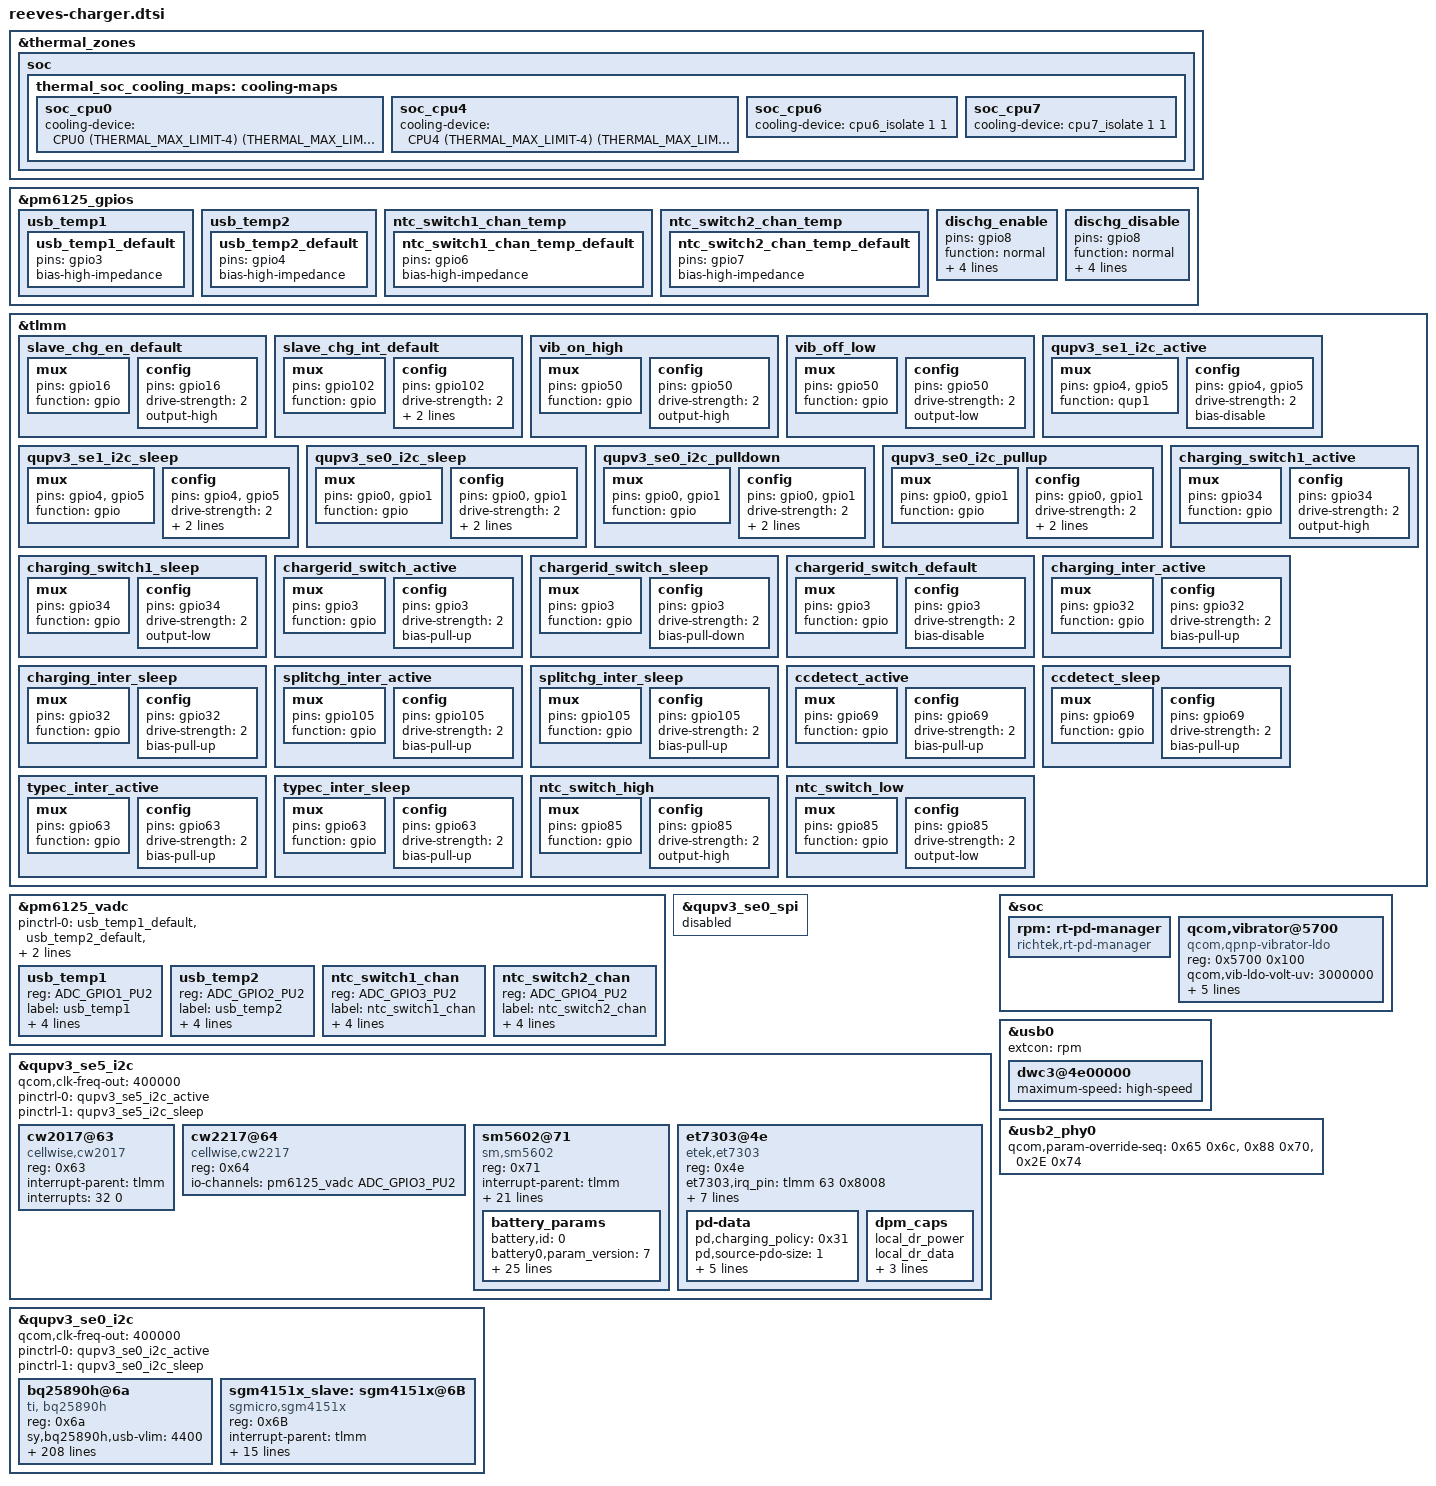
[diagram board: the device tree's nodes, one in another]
/*
&smb1355 {
	/delete-property/ pinctrl-names;
	/delete-property/ pinctrl-0;
	/delete-property/ interrupt-parent;
	/delete-property/ interrupts;
	/delete-property/ status;

	status = "disabled";
};

&smb1355_charger {
	/delete-property/ pinctrl-names;
	/delete-property/ pinctrl-0;
	/delete-property/ qcom,parallel-mode;
	/delete-property/ qcom,disable-ctm;
	/delete-property/ qcom,hw-die-temp-mitigation;
	/delete-property/ status;

	status = "disabled";
};


&dsi_td4330_truly_v2_video {
	/delete-property/ qcom,platform-bklight-en-gpio;
};

&dsi_td4330_truly_v2_cmd {
	/delete-property/ qcom,platform-bklight-en-gpio;
};

&sde_dsi {
	/delete-property/ lab-supply;
	/delete-property/ ibb-supply;
};
*/
&thermal_zones {
	soc {
		thermal_soc_cooling_maps: cooling-maps {
			soc_cpu0 {
				//trip = <&pmi632_low_soc>;
				cooling-device =
					<&CPU0 (THERMAL_MAX_LIMIT-4)
						(THERMAL_MAX_LIMIT-4)>;
			};

			soc_cpu4 {
				//trip = <&pmi632_low_soc>;
				cooling-device =
					<&CPU4 (THERMAL_MAX_LIMIT-4)
						(THERMAL_MAX_LIMIT-4)>;
			};

			soc_cpu6 {
				//trip = <&pmi632_low_soc>;
				cooling-device = <&cpu6_isolate 1 1>;
			};

			soc_cpu7 {
				//trip = <&pmi632_low_soc>;
				cooling-device = <&cpu7_isolate 1 1>;
			};
		};
	};
};

/*split charger dts config*/
&pm6125_gpios {
	usb_temp1 {
		usb_temp1_default: usb_temp1_default {
			pins = "gpio3";
			bias-high-impedance;
		};
	};

	usb_temp2 {
		usb_temp2_default: usb_temp2_default {
			pins = "gpio4";
			bias-high-impedance;
		};
	};

	ntc_switch1_chan_temp {
		ntc_switch1_chan_temp_default: ntc_switch1_chan_temp_default {
			pins = "gpio6";
			bias-high-impedance;
		};
	};

	ntc_switch2_chan_temp {
		ntc_switch2_chan_temp_default: ntc_switch2_chan_temp_default {
			pins = "gpio7";
			bias-high-impedance;
		};
	};

	dischg_enable: dischg_enable {
		pins = "gpio8";
		function = "normal";
		power-source = <0>;
		output-high;
		input-disable;
		qcom,drive-strength = <2>;
	};

	dischg_disable: dischg_disable {
		pins = "gpio8";
		function = "normal";
		power-source = <0>;
		output-low;
		input-disable;
		qcom,drive-strength = <2>;
	};
};

&tlmm {
			slave_chg_en_default: slave_chg_en_default {
				mux {
					pins = "gpio16";
					function = "gpio";
				};

				config {
					pins = "gpio16";
					drive-strength = <2>;
					output-high;
				};
			};

			slave_chg_int_default: slave_chg_int_default {
				mux {
					pins = "gpio102";
					function = "gpio";
				};

				config {
					pins = "gpio102";
					drive-strength = <2>;
					input-enable;
					bias-pull-up;
				};
			};


			vib_on_high: vib_on_high {
				mux {
					pins = "gpio50";
					function = "gpio";
				};

				config {
					pins = "gpio50";
					drive-strength = <2>;
					output-high;
				};
			};
			vib_off_low: vib_off_low {
				mux {
					pins = "gpio50";
					function = "gpio";
				};

				config {
					pins = "gpio50";
					drive-strength = <2>;
					output-low;
				};
			};
			qupv3_se1_i2c_active: qupv3_se1_i2c_active {
				mux {
					pins = "gpio4", "gpio5";
					function = "qup1";
				};

				config {
					pins = "gpio4", "gpio5";
					drive-strength = <2>;
					bias-disable;
				};
			};
			qupv3_se1_i2c_sleep: qupv3_se1_i2c_sleep {
				mux {
					pins = "gpio4", "gpio5";
					function = "gpio";
				};

				config {
					pins = "gpio4", "gpio5";
					drive-strength = <2>;
					bias-no-pull;
					output-high;
				};
			};
			qupv3_se0_i2c_sleep: qupv3_se0_i2c_sleep {
				mux {
					pins = "gpio0", "gpio1";
					function = "gpio";
				};

				config {
					pins = "gpio0", "gpio1";
					drive-strength = <2>;
					bias-no-pull;
					output-high;
				};
			};

			qupv3_se0_i2c_pulldown: qupv3_se0_i2c_pulldown {
				mux {
					pins = "gpio0", "gpio1";
					function = "gpio";
				};

				config {
					pins = "gpio0", "gpio1";
					drive-strength = <2>;
					bias-pull-down;
					output-low;
				};
			};

			qupv3_se0_i2c_pullup: qupv3_se0_i2c_pullup {
				mux {
					pins = "gpio0", "gpio1";
					function = "gpio";
				};

				config {
					pins = "gpio0", "gpio1";
					drive-strength = <2>;
					bias-pull-up;
					input-enable;
				};
			};

			charging_switch1_active: charging_switch1_active {
				mux {
					pins = "gpio34";
					function = "gpio";
				};

				config {
					pins = "gpio34";
					drive-strength = <2>;
					output-high;
				};
			};

			charging_switch1_sleep: charging_switch1_sleep {
				mux {
					pins = "gpio34";
					function = "gpio";
				};

				config {
					pins = "gpio34";
					drive-strength = <2>;
					output-low;
				};
			};

			chargerid_switch_active: chargerid_switch_active {
				mux {
					pins = "gpio3";
					function = "gpio";
				};

				config {
					pins = "gpio3";
					drive-strength = <2>;
					bias-pull-up;
				};
			};

			chargerid_switch_sleep: chargerid_switch_sleep {
				mux {
					pins = "gpio3";
					function = "gpio";
				};

				config {
					pins = "gpio3";
					drive-strength = <2>;
					bias-pull-down;
				};
			};

			chargerid_switch_default: chargerid_switch_default {
				mux {
					pins = "gpio3";
					function = "gpio";
				};

				config {
					pins = "gpio3";
					drive-strength = <2>;
					bias-disable; /* NO PULL */
				};
			};

             charging_inter_active: charging_inter_active {
                     mux {
                             pins = "gpio32";
                             function = "gpio";
                     };

                     config {
                             pins = "gpio32";
                             drive-strength = <2>;
                             bias-pull-up;
                     };
             };

             charging_inter_sleep: charging_inter_sleep {
                     mux {
                             pins = "gpio32";
                             function = "gpio";
                     };

                     config {
                             pins = "gpio32";
                             drive-strength = <2>;
                             bias-pull-up;
                     };
            };

             /*split_chg*/
             splitchg_inter_active: splitchg_inter_active {
                     mux {
                             pins = "gpio105";
                             function = "gpio";
                     };

                     config {
                             pins = "gpio105";
                             drive-strength = <2>;
                             bias-pull-up;
                     };
             };

             splitchg_inter_sleep: splitchg_inter_sleep {
                     mux {
                             pins = "gpio105";
                             function = "gpio";
                     };

                     config {
                             pins = "gpio105";
                             drive-strength = <2>;
                             bias-pull-up;
                     };
            };

             ccdetect_active: ccdetect_active {
                     mux {
                             pins = "gpio69";
                             function = "gpio";
                     };

                     config {
                             pins = "gpio69";
                             drive-strength = <2>;
                             bias-pull-up;
                     };
             };

             ccdetect_sleep: ccdetect_sleep {
                     mux {
                             pins = "gpio69";
                             function = "gpio";
                     };

                     config {
                             pins = "gpio69";
                             drive-strength = <2>;
                             bias-pull-up;
                     };
            };

             typec_inter_active: typec_inter_active {
                     mux {
                             pins = "gpio63";
                             function = "gpio";
                     };

                     config {
                             pins = "gpio63";
                             drive-strength = <2>;
                             bias-pull-up;
                     };
             };

             typec_inter_sleep: typec_inter_sleep {
                     mux {
                             pins = "gpio63";
                             function = "gpio";
                     };

                     config {
                             pins = "gpio63";
                             drive-strength = <2>;
                             bias-pull-up;
                     };
            };

			ntc_switch_high: ntc_switch_high {
				mux {
					pins = "gpio85";
					function = "gpio";
				};

				config {
					pins = "gpio85";
					drive-strength = <2>;
					output-high;
				};
			};

			ntc_switch_low: ntc_switch_low {
				mux {
					pins = "gpio85";
					function = "gpio";
				};

				config {
					pins = "gpio85";
					drive-strength = <2>;
					output-low;
				};
			};
};

&pm6125_vadc {
	pinctrl-0 = <&usb_temp1_default &usb_temp2_default &ntc_switch1_chan_temp_default &ntc_switch2_chan_temp_default>;

	usb_temp1 {
		reg = <ADC_GPIO1_PU2>;
		label = "usb_temp1";
		qcom,ratiometric;
		qcom,hw-settle-time = <200>;
		qcom,pre-scaling = <1 1>;
		qcom,scale-fn-type = <ADC_SCALE_HW_CALIB_DEFAULT>;
	};

	usb_temp2 {
		reg = <ADC_GPIO2_PU2>;
		label = "usb_temp2";
		qcom,ratiometric;
		qcom,hw-settle-time = <200>;
		qcom,pre-scaling = <1 1>;
		qcom,scale-fn-type = <ADC_SCALE_HW_CALIB_DEFAULT>;
	};

	ntc_switch1_chan {
		reg = <ADC_GPIO3_PU2>;
		label = "ntc_switch1_chan";
		qcom,ratiometric;
		qcom,hw-settle-time = <200>;
		qcom,pre-scaling = <1 1>;
		qcom,scale-fn-type = <ADC_SCALE_HW_CALIB_DEFAULT>;
	};

	ntc_switch2_chan {
		reg = <ADC_GPIO4_PU2>;
		label = "ntc_switch2_chan";
		qcom,ratiometric;
		qcom,hw-settle-time = <200>;
		qcom,pre-scaling = <1 1>;
		qcom,scale-fn-type = <ADC_SCALE_HW_CALIB_DEFAULT>;
	};
};

&qupv3_se0_spi {
	status = "disabled";
};

&qupv3_se5_i2c {
	status = "okay";
	qcom,clk-freq-out = <400000>;
	pinctrl-names = "default", "sleep";
	pinctrl-0 = <&qupv3_se5_i2c_active>;
	pinctrl-1 = <&qupv3_se5_i2c_sleep>;

	cw2017@63 {
		status = "okay";
		compatible = "cellwise,cw2017";
		reg = <0x63>;
		interrupt-parent = <&tlmm>;
		interrupts = <32 0>;
	};

	cw2217@64 {
		status = "okay";
		compatible = "cellwise,cw2217";
		reg = <0x64>;
		io-channels = <&pm6125_vadc ADC_GPIO3_PU2>;
		io-channel-names = "batt_id_chan";
	};

	sm5602@71 {
		compatible = "sm,sm5602";
		reg = <0x71>;
		interrupt-parent = <&tlmm>;
		interrupts = <32 0>;
		qcom,irq-gpio = <&tlmm 32 0x0>;
		io-channels = <&pm6125_vadc ADC_GPIO3_PU2>;
		io-channel-names = "ntc_switch1_chan";
		sm,en_temp_ex;
		//sm,en_temp_in;
		sm,en_batt_det;
		//sm,iocv_man_mode;
		sm,misc = <0x0800>;
		sm,aging_ctrl = <0x0125>;
		sm,cycle_cfg = <0x7000>;
		sm,rsns = <0>;
		sm,fg_irq_set = <0x07FF>;
		sm,low_soc1 = <1>;
		sm,low_soc2 = <15>;
		sm,v_l_alarm = <3400>;
		sm,v_h_alarm = <4400>;
		sm,battery_table_num = <0>;
		sm,param_version = <3>;
		sm,t_l_alarm_in = <54>;
		sm,t_h_alarm_in = <1>;
		sm,t_l_alarm_ex = <0xD3D8>;
		sm,t_h_alarm_ex = <0x9245>;
		sm,shutdown-delay-enable;
		battery_params {
		battery,id = <0>;
		battery0,param_version = <7>;
		battery0,max_voltage_uv = <4435000>;
		battery0,battery_type = <4435 0x0 0x39A6>;
		battery0,battery_table0 = <0x1400 0x1ABE 0x1B53 0x1C6E 0x1D63 0x1D88 0x1D91 0x1D97 0x1DC2 0x1DEC 0x1E52 0x1E7B 0x1EE9 0x1F37 0x1F80 0x1FDA 0x2005 0x20CF 0x217F 0x21F7 0x2250 0x22F4 0x2344 0x24CC>;
		battery0,battery_table1 = <0x0 0x7D 0xFB 0x275 0x4EC 0x6E4 0x8DD 0xB53 0xE48 0x11BB 0x1E0C 0x256F 0x31C0 0x36AD 0x3924 0x3E11 0x4087 0x4A62 0x51C5 0x56B2 0x5A25 0x610B 0x6400 0x64E6>;
		battery0,battery_table2 = <0x1B2C 0x1416 0x1112 0x0E0F 0x0D0E 0x0C0D 0x0C0C 0x0B0B>;
		battery0,alpha = <0x00CC>;
		battery0,beta = <0x0025>;
		battery0,rs = <0x005F>;
		battery0,rs_value = <0x0050 0x010A 0x3800 0x0048>;
		battery0,vit_period = <0x315A>;
		battery0,volt_cal = <0x8000>;
		battery0,mix_value = <0x0003>;
		battery0,curr_offset = <0x000>;
		battery0,curr_slope = <0x8088>;
		battery0,topoff_soc = <7 500>;
		battery0,temp_std = <25>;
		battery0,temp_offset = <0 11 1 0 8 (-1)>;
		battery0,temp_cal = <0 6 1 11 (-1) 0 6 1 9 1>;
		battery0,ext_temp_cal = <0 2 1 2 1 1 2 3 2 3>;
		battery0,tem_poff = <3400 100>;
		battery0,thermal_table = <0x6B98 0x666E 0x614E 0x5C40 0x5733 0x522E 0x4D43 0x485D 0x439C 0x3EDB 
									0x3A37 0x35A6 0x3120 0x2CAF 0x2853 0x2411 0x1FD5 0x1BC8 0x17D0 0x13F7 
									0x103D 0x0C7D 0x08E6 0x0556 0x01DB 0xF645 0xF301 0xEFDC 0xECAA 0xE9A9 
									0xE6BA 0xE3E2 0xE123 0xDE6E 0xDBD9 0xD957 0xD6E3 0xD487 0xD23F 0xD001 
									0xCDD5 0xCBC4 0xC9BB 0xC7C9 0xC5E3 0xC413 0xC24E 0xC098 0xBEF1 0xBD54 
									0xBBCA 0xBA4D 0xB8D8 0xB774 0xB61B 0xB4CC 0xB38A 0xB252 0xB122 0xB002 
									0xAEE9 0xADD9 0xACD0 0xABD1 0xAADE 0xA9F3 0xA90E 0xA831 0xA758 0xA687 
									0xA5C2 0xA501 0xA44A 0xA392 0xA2E5 0xA23F 0xA19C 0xA0FF 0xA068 0x9FD7 
									0x9F49 0x9EC0 0x9E37 0x9DB6 0x9D3B 0x9CC4 0x9C52 0x9BE0 0x9B72 0x9B0A 
									0x9AA3 0x9A42 0x99E2 0x9986 0x992F 0x98D9 0x9885 0x9835 0x97E4 0x9798 
									0x974F 0x9709 0x96C4 0x9682 0x9642 0x9603 0x95C6 0x958B >;  					//NTC value(DEC) table -20~87
		};
	};

	et7303@4e {
	compatible = "etek,et7303";
	reg = <0x4e>;
	/*et7303,irq_pin = <&gpio1 RK_PB2 IRQ_TYPE_LEVEL_LOW>;*/
	et7303,irq_pin = <&tlmm 63 0x8008>;
	rt1711h,en_pwr = <&tlmm 72 0x0>;
	rt-dual,supported_modes = <0>; /* 0: dfp/ufp, 1: dfp, 2: ufp */
	rt-tcpc,name = "type_c_port0"; /* tcpc_device's name */
	rt-tcpc,role_def = <0>; /* 0: SNK Only, 1: SRC Only, 2: DRP, 3: Try.SRC, 4: Try.SNK */
	rt-tcpc,rp_level = <0>; /* 0: Default, 1: 1.5, 2: 3.0 */
	rt-tcpc,vconn_supply  = <0>;  /* 0: Never, 1: Always, 2: EMarkOnly, 3: StartOnly */
	rt-tcpc,notifier_supply_num = <0>; /* the number of notifier supply */
	pd-data {
		/*
			VSAFE5V = 0, MAX_POWER = 1, CUSTOM = 2,
			MAX_POWER_LV = 0x21, MAX_POWER_LVIC = 0x31
			MAX_POWER_HV = 0x41, MAX_POWER_HVIC = 0x51
		*/
		pd,charging_policy = <0x31>;
		pd,source-pdo-size = <1>;
		pd,source-pdo-data = <0x00019032>;

		pd,sink-pdo-size = <2>;
		pd,sink-pdo-data = <0x000190c8 0x0001912c>;

		/*
		No DP, host + device
			pd,id-vdo-size = <3>;
			pd,id-vdo-data = <0xd00029cf 0x0 0x00010000>;
		With DP
			pd,id-vdo-size = <4>;
			pd,id-vdo-data = <0xec0029cf 0x0 0x00010000 0x11000001>;
		*/
		pd,id-vdo-size = <3>;
		pd,id-vdo-data = <0xd8006dcf 0x0 0x00010000>;
	};
	dpm_caps {
		local_dr_power;
		local_dr_data;
		local_usb_comm;
		// local_usb_suspend;
		// local_high_cap;
		// local_give_back;
		// local_no_suspend;
		// local_vconn_supply;

		// attemp_discover_cable_dfp;
		// attemp_enter_dp_mode;
		// attemp_discover_cable;
		// attemp_discover_id;

		/* 0: disable, 1: prefer_snk, 2: prefer_src */
		pr_check = <0>;
		// pr_reject_as_source;
		// pr_reject_as_sink;
		// pr_check_gp_source;
		// pr_check_gp_sink;

		/* 0: disable, 1: prefer_ufp, 2: prefer_dfp */
		dr_check = <0>;
		// dr_reject_as_dfp;
		// dr_reject_as_ufp;
	};
	};
};

&soc {
	rpm: rt-pd-manager {
		compatible = "richtek,rt-pd-manager";
	};
};

&qupv3_se0_i2c {
	status = "okay";
	qcom,clk-freq-out = <400000>;
	pinctrl-names = "default", "sleep";
	pinctrl-0 = <&qupv3_se0_i2c_active>;
	pinctrl-1 = <&qupv3_se0_i2c_sleep>;


	bq25890h@6a {
			status = "okay";
			compatible = "ti, bq25890h";
			reg = <0x6a>;

			sy,bq25890h,usb-vlim =<4400>;
			sy,bq25890h,precharge-current = <256>;
			sy,bq25890h,termination-current = <250>;
			sy,bq25890h,boost-current = <1650>;
			sy,bq25890h,boost-voltage = <5318>;
			sy,bq25890h,charge-detect-enable;

			/*oplus charger config*/
			//test_bob-supply = <&pm8150a_bob>;
			qcom,usb-icl-ua = <3000000>;
			qcom,fcc-max-ua = <3000000>;
			//qcom,fv-max-uv = <4373000>;
			qcom,hvdcp-autonomous-enable;
			qcom,sec-charger-config = <1>;
			qcom,float-option = <1>;

			//for oplus chg framework:
			qcom,input_current_charger_ma = <2000>;
			qcom,pd_input_current_charger_ma = <2000>;
			qcom,qc_input_current_charger_ma = <2000>;
			qcom,input_current_usb_ma = <500>;

			qcom,input_current_led_ma = <1200>;
			qcom,input_current_led_ma_high = <1500>;
			qcom,input_current_led_ma_warm = <2000>;
			qcom,input_current_led_ma_normal = <2000>;

			qcom,input_current_camera_ma = <1200>;
			qcom,input_current_cdp_ma = <1500>;
			//qcom,input_current_led_ma_overtemp = <900>;
			qcom,overtemp_bat_decidegc = <350>;
			qcom,iterm_disabled = <0>;
			sw_full_count = <25>;
			qcom,iterm_ma = <350>;
			qcom,recharge-mv = <100>;
			qcom,batt_capacity_mah = <7100>;/*typical capacity*/
			//qcom,batt_capacity_mah = <4880>; /*rated capacity*/

			qcom,slave_chg_enable_ma = <700>; /*open slave*/
			qcom,slave_chg_disable_ma = <500>; /*close slave*/

			qcom,removed_bat_decidegc = <190>;	/* < -19C */

			qcom,cold_bat_decidegc = <100>;  /*-10C~0C*/
			qcom,temp_cold_vfloat_mv = <4435>;
			qcom,temp_cold_fastchg_current_ma = <1400>;
			qcom,temp_cold_fastchg_current_ma_high = <1400>;
			qcom,temp_cold_fastchg_current_ma_low = <1000>;
			qcom,pd_temp_cold_fastchg_current_ma_high = <1400>;
			qcom,pd_temp_cold_fastchg_current_ma_low = <1000>;
			qcom,qc_temp_cold_fastchg_current_ma_high = <1400>;
			qcom,qc_temp_cold_fastchg_current_ma_low = <1000>;

			qcom,little_cold_bat_decidegc = <0>;	/*0C~5C*/
			qcom,temp_little_cold_vfloat_mv = <4435>;
			qcom,temp_little_cold_fastchg_current_ma_high = <1400>;
			qcom,temp_little_cold_fastchg_current_ma_low = <1000>;
			qcom,temp_little_cold_fastchg_current_ma = <1400>;
			qcom,pd_temp_little_cold_fastchg_current_ma_high = <1400>;
			qcom,pd_temp_little_cold_fastchg_current_ma_low = <1000>;
			qcom,qc_temp_little_cold_fastchg_current_ma_high = <1400>;
			qcom,qc_temp_little_cold_fastchg_current_ma_low = <1000>;

			qcom,cool_bat_decidegc = <50>;	/*5C~12C*/
			qcom,temp_cool_vfloat_mv = <4435>;
			qcom,temp_cool_fastchg_current_ma_high = <1400>;
			qcom,temp_cool_fastchg_current_ma_low = <1000>;
			qcom,pd_temp_cool_fastchg_current_ma_high = <1400>;
			qcom,pd_temp_cool_fastchg_current_ma_low = <1000>;
			qcom,qc_temp_cool_fastchg_current_ma_high = <1400>;
			qcom,qc_temp_cool_fastchg_current_ma_low = <1000>;

			qcom,little_cool_bat_decidegc = <120>;	/*12C~15C*/
			qcom,temp_little_cool_vfloat_mv = <4435>;
			qcom,temp_little_cool_fastchg_current_ma = <1400>;
			qcom,temp_little_cool_fastchg_current_ma_high = <1400>;
			qcom,temp_little_cool_fastchg_current_ma_low = <1000>;
			qcom,pd_temp_little_cool_fastchg_current_ma = <1400>;
			qcom,pd_temp_little_cool_fastchg_current_ma_high = <1400>;
			qcom,pd_temp_little_cool_fastchg_current_ma_low = <1000>;
			qcom,qc_temp_little_cool_fastchg_current_ma = <1400>;
			qcom,qc_temp_little_cool_fastchg_current_ma_high = <1400>;
			qcom,qc_temp_little_cool_fastchg_current_ma_low = <1000>;

			qcom,normal_bat_decidegc = <150>;	/*15C~45C*/
			qcom,temp_normal_fastchg_current_ma = <2100>;
			qcom,temp_normal_vfloat_mv = <4435>;
			qcom,pd_temp_normal_fastchg_current_ma = <3200>;
			qcom,qc_temp_normal_fastchg_current_ma = <3200>;

			qcom,normal_phase1_bat_decidegc = <150>;       /* 15C ~ 22C */
			qcom,temp_normal_phase1_vfloat_mv = <4435>;
			qcom,temp_normal_phase1_fastchg_current_ma = <3200>;

			qcom,normal_phase2_bat_decidegc = <220>;       /* 22C ~ 34C */
			qcom,temp_normal_phase2_vfloat_mv = <4435>;
			qcom,temp_normal_phase2_fastchg_current_ma_high = <3200>;
			qcom,temp_normal_phase2_fastchg_current_ma_low = <3200>;

			qcom,normal_phase3_bat_decidegc = <340>;       /* 34 ~ 37C */
			qcom,temp_normal_phase3_vfloat_mv = <4435>;
			qcom,temp_normal_phase3_fastchg_current_ma_high = <3200>;
			qcom,temp_normal_phase3_fastchg_current_ma_low = <3200>;

			qcom,normal_phase4_bat_decidegc = <370>;       /* 37C ~ 40C */
			qcom,temp_normal_phase4_vfloat_mv = <4435>;
			qcom,temp_normal_phase4_fastchg_current_ma_high = <3200>;
			qcom,temp_normal_phase4_fastchg_current_ma_low = <3200>;

			qcom,normal_phase5_bat_decidegc = <400>;       /* 40C ~ 45C */
			qcom,temp_normal_phase5_vfloat_mv = <4435>;
			qcom,temp_normal_phase5_fastchg_current_ma = <3200>;

			qcom,normal_phase6_bat_decidegc = <450>;       /* 45C ~ 53C */
			qcom,temp_normal_phase6_vfloat_mv = <4435>;
			qcom,temp_normal_phase6_fastchg_current_ma = <3200>;

			qcom,warm_bat_decidegc = <450>;		/*45C~53C*/ /*8pin Bat Vooc project need add 3 degree C*/
			qcom,temp_warm_vfloat_mv = <4130>;
			qcom,temp_warm_fastchg_current_ma = <3200>;
			qcom,pd_temp_warm_fastchg_current_ma = <3200>;
			qcom,qc_temp_warm_fastchg_current_ma = <3200>;
			qcom,temp_warm_fastchg_current_ma_led_on = <3200>;

			qcom,hot_bat_decidegc = <530>;

			qcom,support_3p6_standard;

			qcom,non_standard_vfloat_mv = <3980>;
			qcom,non_standard_fastchg_current_ma = <512>;
			qcom,short_c_bat_cv_mv = <4330>;
			qcom,short_c_bat_vfloat_mv = <3800>;
			qcom,short_c_bat_fastchg_current_ma = <512>;

			qcom,cold_vfloat_sw_limit = <4385>;
			qcom,little_cold_vfloat_sw_limit = <4385>;
			qcom,cool_vfloat_sw_limit = <4385>;
			qcom,little_cool_vfloat_sw_limit = <4385>;
			qcom,normal_vfloat_sw_limit = <4385>;
			qcom,warm_vfloat_sw_limit = <4080>;
			qcom,non_standard_vfloat_sw_limit = <4385>;
			qcom,short_c_bat_vfloat_sw_limit = <3750>;

			qcom,max_chg_time_sec = <72000>;
			qcom,charger_hv_thr = <10000>;
			qcom,charger_recv_thr = <9800>;
			qcom,charger_lv_thr = <3400>;
			qcom,vbatt_full_thr = <4435>;
			qcom,vbatt_hv_thr = <4550>;
			qcom,vfloat_step_mv = <8>;
			qcom,non_standard_vfloat_over_sw_limit = <3990>;
			qcom,cold_vfloat_over_sw_limit = <4445>;
			qcom,little_cold_vfloat_over_sw_limit = <4445>;
			qcom,cool_vfloat_over_sw_limit = <4445>;
			qcom,little_cool_vfloat_over_sw_limit = <4445>;
			qcom,normal_vfloat_over_sw_limit = <4445>;
			qcom,warm_vfloat_over_sw_limit = <4140>;

			qcom,vbatt_power_off = <3300>;
			qcom,vbatt_soc_1 = <3410>;
			qcom,vbatt_num = <1>;
			qcom,smart_charging_screenoff;
			qcom,dual_charger_support;
			qcom,normal_vterm_hw_inc = <18>;
			qcom,non_normal_vterm_hw_inc = <18>;


			qcom,default_iterm_ma = <350>;
			qcom,default_temp_normal_fastchg_current_ma = <2100>;
			qcom,default_normal_vfloat_sw_limit = <4385>;
			qcom,default_temp_normal_vfloat_mv = <4435>;
			qcom,default_normal_vfloat_over_sw_limit = <4445>;

			qcom,default_temp_little_cool_fastchg_current_ma = <1400>;
			qcom,default_little_cool_vfloat_sw_limit = <4385>;
			qcom,default_temp_little_cool_vfloat_mv = <4435>;
			qcom,default_little_cool_vfloat_over_sw_limit = <4445>;

			qcom,vbatt_pdqc_to_5v_thr = <4435>;
			qcom,vbatt_pdqc_to_9v_thr = <4500>;
			qcom,tbatt_pdqc_to_5v_thr = <530>;
			///qcom,offset_temp = <30>;
			//for control:
			//qcom,suspend_after_full;
			qcom,check_batt_full_by_sw;
			qcom,external_gauge;
			qcom,chg_ctrl_by_lcd;
			qcom,chg_ctrl_by_camera;
			qcom,sw_vfloat_over_protect_enable;
			qcom,lpd-disable;

			qcom,usbtemp_batttemp_gap = <12>;
			qcom,usbtemp_temp_up_time_thr = <30>;
			qcom,usbtemp_max_temp_thr = <57>;

			//qcom,vooc_show_ui_soc_decimal;
			qcom,ui_soc_decimal_speedmin = <20>;//2A

			//qcom,chargerid_switch-gpio = <&tlmm 3 0x00>;
			qcom,dischg-gpio = <&pm6125_gpios 8 0x00>;

			//bq25890h irq
			qcom,chg_irq_gpio = <&tlmm 105 0x00>;
			interrupt-parent = <&tlmm>;
			interrupts = <105 0>;

			qcom,ccdetect-gpio = <&tlmm 69 0x00>;
			//interrupts = <69 0>;

			//ntc switch gpio
			qcom,ntc-switch-gpio = <&tlmm 85 0x00>;

			screen_off_control_by_batt_temp;

			pinctrl-names = "chargerid_switch_active", "chargerid_switch_sleep", "chargerid_switch_default",
							"dischg_enable", "dischg_disable", "splitchg_inter_active", "splitchg_inter_sleep",
							"ntc_switch_high", "ntc_switch_low",
							"ccdetect_active", "ccdetect_sleep";

			pinctrl-0 = <&chargerid_switch_active>;
			pinctrl-1 = <&chargerid_switch_sleep>;
			pinctrl-2 = <&chargerid_switch_default>;
			pinctrl-3 = <&dischg_enable>;
			pinctrl-4 = <&dischg_disable>;
			pinctrl-5 = <&splitchg_inter_active>;
			pinctrl-6 = <&splitchg_inter_sleep>;
			pinctrl-7 = <&ntc_switch_high>;
			pinctrl-8 = <&ntc_switch_low>;
			pinctrl-9 = <&ccdetect_active>;
			pinctrl-10 = <&ccdetect_sleep>;

			io-channels = <&pm6125_vadc ADC_GPIO1_PU2>,
				<&pm6125_vadc ADC_GPIO2_PU2>,
				<&pm6125_vadc ADC_GPIO4_PU2>;
			io-channel-names = "usb_temp1",
				"usb_temp2",
				"ntc_switch2_chan";
			dpdm-supply = <&usb2_phy0>;
	};
	sgm4151x_slave: sgm4151x@6B {
		status = "okay";
		compatible = "sgmicro,sgm4151x";
		reg = <0x6B>;
		interrupt-parent = <&tlmm>;
		interrupts = <102 0>;
		intr-gpio = <&tlmm 102 0>;
		chg-en-gpio = <&tlmm 16 0>;
		pinctrl-names = "default";
		pinctrl-0 = <&slave_chg_en_default &slave_chg_int_default>;

		sgm4151x,charge-voltage = <4432>;
		sgm4151x,charge-current = <500>;
		sgm4151x,term-current = <350>;
		sgm4151x,prechg_current = <240>;
		sgm4151x,enable-auto-dpdm;
		sgm4151x,enable-termination;
		sgm4151x,enable-ico;
		sgm4151x,use-absolute-vindpm;
		sgm4151x,otg_vol = <5000>;
		sgm4151x,otg_current = <500>;
	};
};

/*load vibrator for rm pmic*/
&soc {
	qcom,vibrator@5700 {
			compatible = "qcom,qpnp-vibrator-ldo";
			reg = <0x5700 0x100>;
			qcom,vib-ldo-volt-uv = <3000000>;
			qcom,disable-overdrive;
			qcom,vib-type = <1>;	/*0:ldo 1:gpio*/
			status = "okay";

			qcom,vibrator_switch-gpio = <&tlmm 50 0x00>;
			pinctrl-names = "vib_on_high", "vib_off_low";
			pinctrl-0 = <&vib_on_high>;
			pinctrl-1 = <&vib_off_low >;
	};
};

&usb0 {
	extcon = <&rpm>;
	dwc3@4e00000 {
		maximum-speed = "high-speed";
	};
};

&usb2_phy0 {
	qcom,param-override-seq = <0x65 0x6c>, //override_x0
				  <0x88 0x70>, //override_x1
				  <0x2E 0x74>; //override_x2
};

